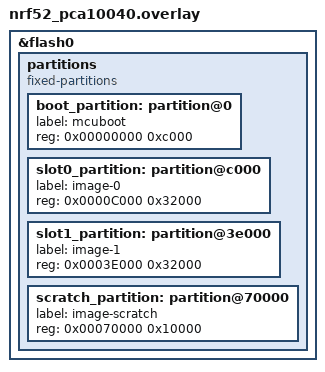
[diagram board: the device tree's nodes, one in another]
&flash0 {
	/*
	 * For more information, see:
	 * http://docs.zephyrproject.org/latest/devices/dts/flash_partitions.html
	 */
	partitions {
		compatible = "fixed-partitions";
		#address-cells = <1>;
		#size-cells = <1>;

		boot_partition: partition@0 {
			label = "mcuboot";
			reg = <0x00000000 0xc000>;
		};
		slot0_partition: partition@c000 {
			label = "image-0";
			reg = <0x0000C000 0x32000>;
		};
		slot1_partition: partition@3e000 {
			label = "image-1";
			reg = <0x0003E000 0x32000>;
		};
		scratch_partition: partition@70000 {
			label = "image-scratch";
			reg = <0x00070000 0x10000>;
		};
	};
};
